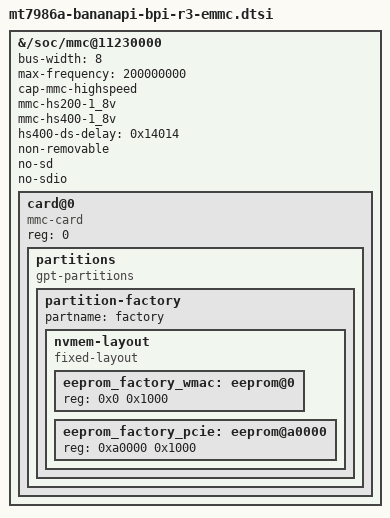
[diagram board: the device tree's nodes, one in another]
// SPDX-License-Identifier: (GPL-2.0 OR MIT)
/*
 * Copyright (C) 2021 MediaTek Inc.
 * Author: Sam.Shih <sam.shih@mediatek.com>
 */

/*
This is copied from linux where it is an overlay, unfortunatly it is not
possible to use dtbo in sysboot unless present in syslinux.conf
*/
&{/soc/mmc@11230000} {
        bus-width = <8>;
        max-frequency = <200000000>;
        cap-mmc-highspeed;
        mmc-hs200-1_8v;
        mmc-hs400-1_8v;
        hs400-ds-delay = <0x14014>;
        non-removable;
        no-sd;
        no-sdio;
        status = "okay";

        #address-cells = <1>;
        #size-cells = <0>;

        card@0 {
                compatible = "mmc-card";
                reg = <0>;

                partitions {
                        compatible = "gpt-partitions";

                        partition-factory {
                                partname = "factory";

                                nvmem-layout {
                                        compatible = "fixed-layout";
                                        #address-cells = <1>;
                                        #size-cells = <1>;

                                        eeprom_factory_wmac: eeprom@0 {
                                                reg = <0x0 0x1000>;
                                        };

                                        eeprom_factory_pcie: eeprom@a0000 {
                                                reg = <0xa0000 0x1000>;
                                        };
                                };
                        };
                };
        };
};
